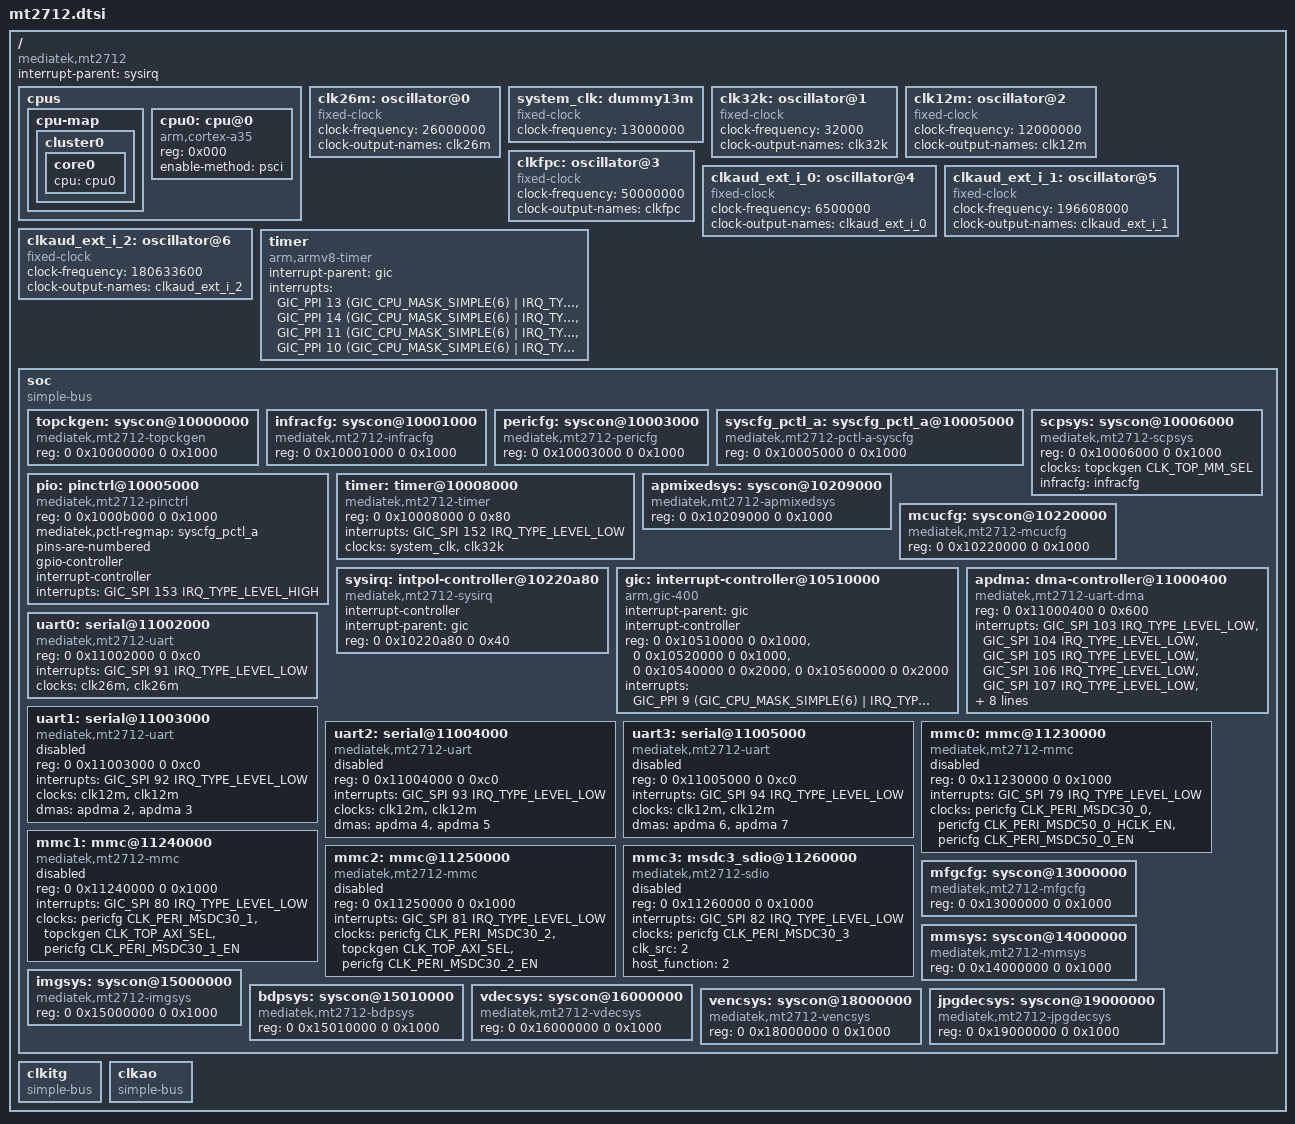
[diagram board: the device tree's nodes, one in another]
/*
 * Copyright (c) 2017 MediaTek Inc.
 * Author: Eddie Huang <eddie.huang@mediatek.com>
 *
 * This program is free software; you can redistribute it and/or modify
 * it under the terms of the GNU General Public License version 2 as
 * published by the Free Software Foundation.
 *
 * This program is distributed in the hope that it will be useful,
 * MERCHANTABILITY or FITNESS FOR A PARTICULAR PURPOSE.  See the
 * GNU General Public License for more details.
 */

#include <dt-bindings/clock/mt2712-clk.h>
#include <dt-bindings/interrupt-controller/irq.h>
#include <dt-bindings/interrupt-controller/arm-gic.h>
#include <dt-bindings/memory/mt2712-larb-port.h>
#include <dt-bindings/power/mt2712-power.h>
#include <dt-bindings/reset-controller/mt2712-resets.h>
#include "mt2712-pinfunc.h"

/ {
	compatible = "mediatek,mt2712";
	interrupt-parent = <&sysirq>;
	#address-cells = <2>;
	#size-cells = <2>;

	cpus {
		#address-cells = <1>;
		#size-cells = <0>;

		cpu-map {
			cluster0 {
				core0 {
					cpu = <&cpu0>;
				};
			};
		};

		cpu0: cpu@0 {
			device_type = "cpu";
			compatible = "arm,cortex-a35";
			reg = <0x000>;
			enable-method = "psci";
		};
	};

	clk26m: oscillator@0 {
		compatible = "fixed-clock";
		#clock-cells = <0>;
		clock-frequency = <26000000>;
		clock-output-names = "clk26m";
	};

	system_clk: dummy13m {
		compatible = "fixed-clock";
		clock-frequency = <13000000>;
		#clock-cells = <0>;
	};

	clk32k: oscillator@1 {
		compatible = "fixed-clock";
		#clock-cells = <0>;
		clock-frequency = <32000>;
		clock-output-names = "clk32k";
	};

	clk12m: oscillator@2 {
		compatible = "fixed-clock";
		#clock-cells = <0>;
		clock-frequency = <12000000>;
		clock-output-names = "clk12m";
	};

	clkfpc: oscillator@3 {
		compatible = "fixed-clock";
		#clock-cells = <0>;
		clock-frequency = <50000000>;
		clock-output-names = "clkfpc";
	};

	clkaud_ext_i_0: oscillator@4 {
		compatible = "fixed-clock";
		#clock-cells = <0>;
		clock-frequency = <6500000>;
		clock-output-names = "clkaud_ext_i_0";
	};

	clkaud_ext_i_1: oscillator@5 {
		compatible = "fixed-clock";
		#clock-cells = <0>;
		clock-frequency = <196608000>;
		clock-output-names = "clkaud_ext_i_1";
	};

	clkaud_ext_i_2: oscillator@6 {
		compatible = "fixed-clock";
		#clock-cells = <0>;
		clock-frequency = <180633600>;
		clock-output-names = "clkaud_ext_i_2";
	};

	timer {
		compatible = "arm,armv8-timer";
		interrupt-parent = <&gic>;
		interrupts = <GIC_PPI 13
			      (GIC_CPU_MASK_SIMPLE(6) | IRQ_TYPE_LEVEL_LOW)>,
			     <GIC_PPI 14
			      (GIC_CPU_MASK_SIMPLE(6) | IRQ_TYPE_LEVEL_LOW)>,
			     <GIC_PPI 11
			      (GIC_CPU_MASK_SIMPLE(6) | IRQ_TYPE_LEVEL_LOW)>,
			     <GIC_PPI 10
			      (GIC_CPU_MASK_SIMPLE(6) | IRQ_TYPE_LEVEL_LOW)>;
	};

	soc {
		#address-cells = <2>;
		#size-cells = <2>;
		compatible = "simple-bus";
		ranges;

		topckgen: syscon@10000000 {
			compatible = "mediatek,mt2712-topckgen", "syscon";
			reg = <0 0x10000000 0 0x1000>;
			#clock-cells = <1>;
		};

		infracfg: syscon@10001000 {
			compatible = "mediatek,mt2712-infracfg", "syscon";
			reg = <0 0x10001000 0 0x1000>;
			#clock-cells = <1>;
		};

		pericfg: syscon@10003000 {
			compatible = "mediatek,mt2712-pericfg", "syscon";
			reg = <0 0x10003000 0 0x1000>;
			#clock-cells = <1>;
		};

		syscfg_pctl_a: syscfg_pctl_a@10005000 {
			compatible = "mediatek,mt2712-pctl-a-syscfg", "syscon";
			reg = <0 0x10005000 0 0x1000>;
		};

		pio: pinctrl@10005000 {
			compatible = "mediatek,mt2712-pinctrl";
			reg = <0 0x1000b000 0 0x1000>;
			mediatek,pctl-regmap = <&syscfg_pctl_a>;
			pins-are-numbered;
			gpio-controller;
			#gpio-cells = <2>;
			interrupt-controller;
			#interrupt-cells = <2>;
			interrupts = <GIC_SPI 153 IRQ_TYPE_LEVEL_HIGH>;
		};

		scpsys: syscon@10006000 {
			compatible = "mediatek,mt2712-scpsys", "syscon";
			#power-domain-cells = <1>;
			reg = <0 0x10006000 0 0x1000>;
			clocks = <&topckgen CLK_TOP_MM_SEL>;
			clock-names = "mm";
			infracfg = <&infracfg>;
		};

		timer: timer@10008000 {
			compatible = "mediatek,mt2712-timer",
				     "mediatek,mt6577-timer";
			reg = <0 0x10008000 0 0x80>;
			interrupts = <GIC_SPI 152 IRQ_TYPE_LEVEL_LOW>;
			clocks = <&system_clk>, <&clk32k>;
		};

		apmixedsys: syscon@10209000 {
			compatible = "mediatek,mt2712-apmixedsys", "syscon";
			reg = <0 0x10209000 0 0x1000>;
			#clock-cells = <1>;
		};

		mcucfg: syscon@10220000 {
			compatible = "mediatek,mt2712-mcucfg", "syscon";
			reg = <0 0x10220000 0 0x1000>;
			#clock-cells = <1>;
		};

		sysirq: intpol-controller@10220a80 {
			compatible = "mediatek,mt2712-sysirq",
				     "mediatek,mt6577-sysirq";
			interrupt-controller;
			#interrupt-cells = <3>;
			interrupt-parent = <&gic>;
			reg = <0 0x10220a80 0 0x40>;
		};

		gic: interrupt-controller@10510000 {
			compatible = "arm,gic-400";
			#interrupt-cells = <3>;
			interrupt-parent = <&gic>;
			interrupt-controller;
			reg = <0 0x10510000 0 0x1000>,
			      <0 0x10520000 0 0x1000>,
			      <0 0x10540000 0 0x2000>,
			      <0 0x10560000 0 0x2000>;
			interrupts = <GIC_PPI 9
				(GIC_CPU_MASK_SIMPLE(6) | IRQ_TYPE_LEVEL_HIGH)>;
		};

		apdma: dma-controller@11000400 {
			compatible = "mediatek,mt2712-uart-dma";
			reg = <0 0x11000400 0 0x600>;
			interrupts = <GIC_SPI 103 IRQ_TYPE_LEVEL_LOW>,
				     <GIC_SPI 104 IRQ_TYPE_LEVEL_LOW>,
				     <GIC_SPI 105 IRQ_TYPE_LEVEL_LOW>,
				     <GIC_SPI 106 IRQ_TYPE_LEVEL_LOW>,
				     <GIC_SPI 107 IRQ_TYPE_LEVEL_LOW>,
				     <GIC_SPI 108 IRQ_TYPE_LEVEL_LOW>,
				     <GIC_SPI 109 IRQ_TYPE_LEVEL_LOW>,
				     <GIC_SPI 110 IRQ_TYPE_LEVEL_LOW>,
				     <GIC_SPI 111 IRQ_TYPE_LEVEL_LOW>,
				     <GIC_SPI 112 IRQ_TYPE_LEVEL_LOW>,
				     <GIC_SPI 113 IRQ_TYPE_LEVEL_LOW>,
				     <GIC_SPI 114 IRQ_TYPE_LEVEL_LOW>;
			clocks = <&clk26m>;
			clock-names = "apdma";
			#dma-cells = <1>;
		};

		uart0: serial@11002000 {
			compatible = "mediatek,mt2712-uart";
			reg = <0 0x11002000 0 0xc0>;
			interrupts = <GIC_SPI 91 IRQ_TYPE_LEVEL_LOW>;
			clocks = <&clk26m>, <&clk26m>;
			clock-names = "baud", "bus";
			status = "okay";
		};

		uart1: serial@11003000 {
			compatible = "mediatek,mt2712-uart";
			reg = <0 0x11003000 0 0xc0>;
			interrupts = <GIC_SPI 92 IRQ_TYPE_LEVEL_LOW>;
			clocks = <&clk12m>, <&clk12m>;
			clock-names = "baud", "bus";

			dmas = <&apdma 2
				&apdma 3>;
			dma-names = "tx", "rx";

			status = "disabled";
		};

		uart2: serial@11004000 {
			compatible = "mediatek,mt2712-uart";
			reg = <0 0x11004000 0 0xc0>;
			interrupts = <GIC_SPI 93 IRQ_TYPE_LEVEL_LOW>;
			clocks = <&clk12m>, <&clk12m>;
			clock-names = "baud", "bus";

			dmas = <&apdma 4
				&apdma 5>;
			dma-names = "tx", "rx";

			status = "disabled";
		};

		uart3: serial@11005000 {
			compatible = "mediatek,mt2712-uart";
			reg = <0 0x11005000 0 0xc0>;
			interrupts = <GIC_SPI 94 IRQ_TYPE_LEVEL_LOW>;
			clocks = <&clk12m>, <&clk12m>;
			clock-names = "baud", "bus";

			dmas = <&apdma 6
				&apdma 7>;
			dma-names = "tx", "rx";

			status = "disabled";
		};

		mmc0: mmc@11230000 {
			compatible = "mediatek,mt2712-mmc";
			reg = <0 0x11230000 0 0x1000>;
			interrupts = <GIC_SPI 79 IRQ_TYPE_LEVEL_LOW>;
			clocks = <&pericfg CLK_PERI_MSDC30_0>,
				 <&pericfg CLK_PERI_MSDC50_0_HCLK_EN>,
				 <&pericfg CLK_PERI_MSDC50_0_EN>;
			clock-names = "source", "hclk", "source_cg";
			status = "disabled";
		};

		mmc1: mmc@11240000 {
			compatible = "mediatek,mt2712-mmc";
			reg = <0 0x11240000 0 0x1000>;
			interrupts = <GIC_SPI 80 IRQ_TYPE_LEVEL_LOW>;
			clocks = <&pericfg CLK_PERI_MSDC30_1>,
				 <&topckgen CLK_TOP_AXI_SEL>,
				 <&pericfg CLK_PERI_MSDC30_1_EN>;
			clock-names = "source", "hclk", "source_cg";
			status = "disabled";
		};

		mmc2: mmc@11250000 {
			compatible = "mediatek,mt2712-mmc";
			reg = <0 0x11250000 0 0x1000>;
			interrupts = <GIC_SPI 81 IRQ_TYPE_LEVEL_LOW>;
			clocks = <&pericfg CLK_PERI_MSDC30_2>,
				 <&topckgen CLK_TOP_AXI_SEL>,
				 <&pericfg CLK_PERI_MSDC30_2_EN>;
			clock-names = "source", "hclk", "source_cg";
			status = "disabled";
		};

		mmc3: msdc3_sdio@11260000 {
			compatible = "mediatek,mt2712-sdio";
			reg = <0 0x11260000 0 0x1000>;
			interrupts = <GIC_SPI 82 IRQ_TYPE_LEVEL_LOW>;
			/* power domain always on */
			clocks = <&pericfg CLK_PERI_MSDC30_3>;
			clock-names = "sdio-clock";
			clk_src = <2>;  /*<MSDC30_CLKSRC_200MHZ>*/
			host_function = <2>;
			status = "disabled";
		};

		mfgcfg: syscon@13000000 {
			compatible = "mediatek,mt2712-mfgcfg", "syscon";
			reg = <0 0x13000000 0 0x1000>;
			#clock-cells = <1>;
		};

		mmsys: syscon@14000000 {
			compatible = "mediatek,mt2712-mmsys", "syscon";
			reg = <0 0x14000000 0 0x1000>;
			#clock-cells = <1>;
		};

		imgsys: syscon@15000000 {
			compatible = "mediatek,mt2712-imgsys", "syscon";
			reg = <0 0x15000000 0 0x1000>;
			#clock-cells = <1>;
		};

		bdpsys: syscon@15010000 {
			compatible = "mediatek,mt2712-bdpsys", "syscon";
			reg = <0 0x15010000 0 0x1000>;
			#clock-cells = <1>;
		};

		vdecsys: syscon@16000000 {
			compatible = "mediatek,mt2712-vdecsys", "syscon";
			reg = <0 0x16000000 0 0x1000>;
			#clock-cells = <1>;
		};

		vencsys: syscon@18000000 {
			compatible = "mediatek,mt2712-vencsys", "syscon";
			reg = <0 0x18000000 0 0x1000>;
			#clock-cells = <1>;
		};

		jpgdecsys: syscon@19000000 {
			compatible = "mediatek,mt2712-jpgdecsys", "syscon";
			reg = <0 0x19000000 0 0x1000>;
			#clock-cells = <1>;
		};
	};

	clkitg: clkitg {
		compatible = "simple-bus";
	};

	clkao: clkao {
		compatible = "simple-bus";
	};
};

#include "mt2712-clkitg.dtsi"
#include "mt2712-clkao.dtsi"
